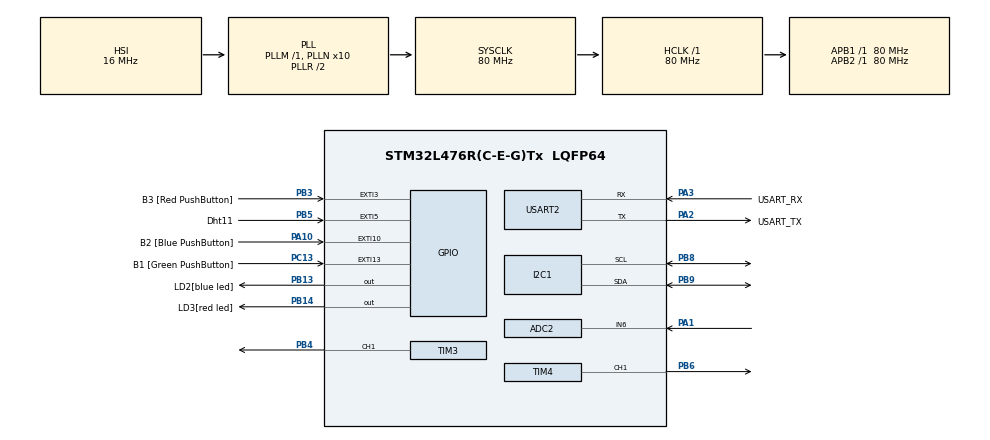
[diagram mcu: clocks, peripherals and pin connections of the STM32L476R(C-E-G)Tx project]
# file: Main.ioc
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ADC2.Channel-0\#ChannelRegularConversion=ADC_CHANNEL_6
ADC2.ClockPrescaler=ADC_CLOCK_ASYNC_DIV64
ADC2.ContinuousConvMode=ENABLE
ADC2.NbrOfConversionFlag=1
ADC2.OffsetNumber-0\#ChannelRegularConversion=ADC_OFFSET_NONE
ADC2.Rank-0\#ChannelRegularConversion=1
ADC2.SamplingTime-0\#ChannelRegularConversion=ADC_SAMPLETIME_2CYCLES_5
I2C1.Timing=0x10909CEC
Mcu.Family=STM32L4
Mcu.Name=STM32L476R(C-E-G)Tx
Mcu.Package=LQFP64
NVIC.ADC1_2_IRQn=true\:0\:0\:false\:false\:true\:true\:true\:true
NVIC.EXTI15_10_IRQn=true\:0\:0\:false\:false\:true\:true\:true\:true
NVIC.EXTI3_IRQn=true\:0\:0\:false\:false\:true\:true\:true\:true
NVIC.EXTI9_5_IRQn=true\:0\:0\:false\:false\:true\:true\:true\:true
NVIC.FLASH_IRQn=true\:0\:0\:false\:false\:true\:true\:true\:true
NVIC.PriorityGroup=NVIC_PRIORITYGROUP_4
NVIC.TIM3_IRQn=true\:0\:0\:false\:false\:true\:true\:true\:true
NVIC.TIM4_IRQn=true\:0\:0\:false\:false\:true\:true\:true\:true
NVIC.TIM6_DAC_IRQn=true\:0\:0\:false\:false\:true\:true\:true\:true
NVIC.USART2_IRQn=true\:0\:0\:false\:false\:true\:true\:true\:true
PA1.Signal=ADCx_IN6
PA10.GPIO_Label=B2 [Blue PushButton]
PA10.GPIO_ModeDefaultEXTI=GPIO_MODE_IT_RISING_FALLING
PA10.Signal=GPXTI10
PA13\ (JTMS-SWDIO).GPIO_Label=TMS
PA13\ (JTMS-SWDIO).Mode=Serial_Wire
PA13\ (JTMS-SWDIO).Signal=SYS_JTMS-SWDIO
PA14\ (JTCK-SWCLK).GPIO_Label=TCK
PA14\ (JTCK-SWCLK).Mode=Serial_Wire
PA14\ (JTCK-SWCLK).Signal=SYS_JTCK-SWCLK
PA2.GPIO_Label=USART_TX
PA2.GPIO_Mode=GPIO_MODE_AF_PP
PA2.GPIO_PuPd=GPIO_NOPULL
PA2.GPIO_Speed=GPIO_SPEED_FREQ_VERY_HIGH
PA2.Mode=Asynchronous
PA2.Signal=USART2_TX
PA3.GPIO_Label=USART_RX
PA3.GPIO_Mode=GPIO_MODE_AF_PP
PA3.GPIO_PuPd=GPIO_NOPULL
PA3.GPIO_Speed=GPIO_SPEED_FREQ_VERY_HIGH
PA3.Mode=Asynchronous
PA3.Signal=USART2_RX
PB13.GPIO_Label=LD2[blue led]
PB13.Signal=GPIO_Output
PB14.GPIO_Label=LD3[red led]
PB14.Signal=GPIO_Output
PB3\ (JTDO-TRACESWO).GPIO_Label=B3 [Red PushButton]
PB3\ (JTDO-TRACESWO).GPIO_ModeDefaultEXTI=GPIO_MODE_IT_FALLING
PB3\ (JTDO-TRACESWO).Signal=GPXTI3
PB4\ (NJTRST).Signal=S_TIM3_CH1
PB5.GPIO_Label=Dht11
PB5.GPIO_ModeDefaultEXTI=GPIO_MODE_IT_FALLING
PB5.Signal=GPXTI5
PB6.Signal=S_TIM4_CH1
PB8.Mode=I2C
PB8.Signal=I2C1_SCL
PB9.Mode=I2C
PB9.Signal=I2C1_SDA
PC13.GPIO_Label=B1 [Green PushButton]
PC13.GPIO_ModeDefaultEXTI=GPIO_MODE_IT_FALLING
PC13.GPIO_PuPd=GPIO_NOPULL
PC13.Signal=GPXTI13
PC14-OSC32_IN\ (PC14).Mode=LSE-External-Oscillator
PC14-OSC32_IN\ (PC14).Signal=RCC_OSC32_IN
PC15-OSC32_OUT\ (PC15).Mode=LSE-External-Oscillator
PC15-OSC32_OUT\ (PC15).Signal=RCC_OSC32_OUT
PH0-OSC_IN\ (PH0).Signal=RCC_OSC_IN
PH1-OSC_OUT\ (PH1).Signal=RCC_OSC_OUT
ProjectManager.HeapSize=0x200
ProjectManager.StackSize=0x400
ProjectManager.TargetToolchain=STM32CubeIDE
RCC.ADCFreq_Value=64000000
RCC.AHBFreq_Value=80000000
RCC.APB1Freq_Value=80000000
RCC.APB1TimFreq_Value=80000000
RCC.APB2Freq_Value=80000000
RCC.APB2TimFreq_Value=80000000
RCC.CortexFreq_Value=80000000
RCC.HCLKFreq_Value=80000000
RCC.HSE_VALUE=8000000
RCC.HSI_VALUE=16000000
RCC.MSI_VALUE=4000000
RCC.PLLN=10
RCC.PLLSourceVirtual=RCC_PLLSOURCE_HSI
RCC.PREFETCH_ENABLE=1
RCC.SYSCLKFreq_VALUE=80000000
RCC.SYSCLKSource=RCC_SYSCLKSOURCE_PLLCLK
RCC.USBFreq_Value=64000000
RCC.VCOOutputFreq_Value=160000000
SH.ADCx_IN6.0=ADC2_IN6,IN6-Single-Ended
SH.S_TIM3_CH1.0=TIM3_CH1,PWM Generation1 CH1
SH.S_TIM4_CH1.0=TIM4_CH1,PWM Generation1 CH1
TIM16.Prescaler=80
TIM3.Channel-PWM\ Generation1\ CH1=TIM_CHANNEL_1
TIM3.Period=100
TIM3.Prescaler=799
TIM3.Pulse-PWM\ Generation1\ CH1=50
TIM4.Channel-PWM\ Generation1\ CH1=TIM_CHANNEL_1
TIM4.Period=100
TIM4.Prescaler=7999
TIM6.Period=10
TIM6.Prescaler=7999
USART2.VirtualMode-Asynchronous=VM_ASYNC
VP_TIM16_VS_ClockSourceINT.Mode=Enable_Timer
VP_TIM3_VS_ClockSourceINT.Mode=Internal
VP_TIM6_VS_ClockSourceINT.Mode=Enable_Timer
board=NUCLEO-L476RG

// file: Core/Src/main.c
/* USER CODE BEGIN Header */
/**
  ******************************************************************************
  * @file           : main.c
  * @brief          : Main program body
  ******************************************************************************
  * @attention
  *
  * Copyright (c) 2022 STMicroelectronics.
  * All rights reserved.
  *
  * This software is licensed under terms that can be found in the LICENSE file
  * in the root directory of this software component.
  * If no LICENSE file comes with this software, it is provided AS-IS.
  *
  ******************************************************************************
  */
/* USER CODE END Header */
#include "main.h"

/* USER CODE BEGIN Includes */
#include "myMain.h"
/* USER CODE END Includes */

 ADC_HandleTypeDef hadc2;

I2C_HandleTypeDef hi2c1;

TIM_HandleTypeDef htim3;
TIM_HandleTypeDef htim4;
TIM_HandleTypeDef htim6;
TIM_HandleTypeDef htim16;

UART_HandleTypeDef huart2;

void SystemClock_Config(void);
static void MX_GPIO_Init(void);
static void MX_USART2_UART_Init(void);
static void MX_TIM6_Init(void);
static void MX_TIM3_Init(void);
static void MX_TIM4_Init(void);
static void MX_ADC2_Init(void);
static void MX_TIM16_Init(void);
static void MX_I2C1_Init(void);

int main(void)
{

  /* MCU Configuration--------------------------------------------------------*/

  /* Reset of all peripherals, Initializes the Flash interface and the Systick. */
  HAL_Init();

  /* Configure the system clock */
  SystemClock_Config();

  /* Initialize all configured peripherals */
  MX_GPIO_Init();
  MX_USART2_UART_Init();
  MX_TIM6_Init();
  MX_TIM3_Init();
  MX_TIM4_Init();
  MX_ADC2_Init();
  MX_TIM16_Init();
  MX_I2C1_Init();
  /* USER CODE BEGIN 2 */
  mainloop();
  /* USER CODE END 2 */

  /* Infinite loop */
  while (1)
  {

  }
}

void SystemClock_Config(void)
{
  RCC_OscInitTypeDef RCC_OscInitStruct = {0};
  RCC_ClkInitTypeDef RCC_ClkInitStruct = {0};

  /** Configure the main internal regulator output voltage
  */
  if (HAL_PWREx_ControlVoltageScaling(PWR_REGULATOR_VOLTAGE_SCALE1) != HAL_OK)
  {
    Error_Handler();
  }

  /** Initializes the RCC Oscillators according to the specified parameters
  * in the RCC_OscInitTypeDef structure.
  */
  RCC_OscInitStruct.OscillatorType = RCC_OSCILLATORTYPE_HSI;
  RCC_OscInitStruct.HSIState = RCC_HSI_ON;
  RCC_OscInitStruct.HSICalibrationValue = RCC_HSICALIBRATION_DEFAULT;
  RCC_OscInitStruct.PLL.PLLState = RCC_PLL_ON;
  RCC_OscInitStruct.PLL.PLLSource = RCC_PLLSOURCE_HSI;
  RCC_OscInitStruct.PLL.PLLM = 1;
  RCC_OscInitStruct.PLL.PLLN = 10;
  RCC_OscInitStruct.PLL.PLLP = RCC_PLLP_DIV7;
  RCC_OscInitStruct.PLL.PLLQ = RCC_PLLQ_DIV2;
  RCC_OscInitStruct.PLL.PLLR = RCC_PLLR_DIV2;
  if (HAL_RCC_OscConfig(&RCC_OscInitStruct) != HAL_OK)
  {
    Error_Handler();
  }

  /** Initializes the CPU, AHB and APB buses clocks
  */
  RCC_ClkInitStruct.ClockType = RCC_CLOCKTYPE_HCLK|RCC_CLOCKTYPE_SYSCLK
                              |RCC_CLOCKTYPE_PCLK1|RCC_CLOCKTYPE_PCLK2;
  RCC_ClkInitStruct.SYSCLKSource = RCC_SYSCLKSOURCE_PLLCLK;
  RCC_ClkInitStruct.AHBCLKDivider = RCC_SYSCLK_DIV1;
  RCC_ClkInitStruct.APB1CLKDivider = RCC_HCLK_DIV1;
  RCC_ClkInitStruct.APB2CLKDivider = RCC_HCLK_DIV1;

  if (HAL_RCC_ClockConfig(&RCC_ClkInitStruct, FLASH_LATENCY_4) != HAL_OK)
  {
    Error_Handler();
  }
}

static void MX_ADC2_Init(void)
{

  ADC_ChannelConfTypeDef sConfig = {0};

  /** Common config
  */
  hadc2.Instance = ADC2;
  hadc2.Init.ClockPrescaler = ADC_CLOCK_ASYNC_DIV64;
  hadc2.Init.Resolution = ADC_RESOLUTION_12B;
  hadc2.Init.DataAlign = ADC_DATAALIGN_RIGHT;
  hadc2.Init.ScanConvMode = ADC_SCAN_DISABLE;
  hadc2.Init.EOCSelection = ADC_EOC_SINGLE_CONV;
  hadc2.Init.LowPowerAutoWait = DISABLE;
  hadc2.Init.ContinuousConvMode = ENABLE;
  hadc2.Init.NbrOfConversion = 1;
  hadc2.Init.DiscontinuousConvMode = DISABLE;
  hadc2.Init.ExternalTrigConv = ADC_SOFTWARE_START;
  hadc2.Init.ExternalTrigConvEdge = ADC_EXTERNALTRIGCONVEDGE_NONE;
  hadc2.Init.DMAContinuousRequests = DISABLE;
  hadc2.Init.Overrun = ADC_OVR_DATA_PRESERVED;
  hadc2.Init.OversamplingMode = DISABLE;
  if (HAL_ADC_Init(&hadc2) != HAL_OK)
  {
    Error_Handler();
  }

  /** Configure Regular Channel
  */
  sConfig.Channel = ADC_CHANNEL_6;
  sConfig.Rank = ADC_REGULAR_RANK_1;
  sConfig.SamplingTime = ADC_SAMPLETIME_2CYCLES_5;
  sConfig.SingleDiff = ADC_SINGLE_ENDED;
  sConfig.OffsetNumber = ADC_OFFSET_NONE;
  sConfig.Offset = 0;
  if (HAL_ADC_ConfigChannel(&hadc2, &sConfig) != HAL_OK)
  {
    Error_Handler();
  }

}

static void MX_I2C1_Init(void)
{

  hi2c1.Instance = I2C1;
  hi2c1.Init.Timing = 0x10909CEC;
  hi2c1.Init.OwnAddress1 = 0;
  hi2c1.Init.AddressingMode = I2C_ADDRESSINGMODE_7BIT;
  hi2c1.Init.DualAddressMode = I2C_DUALADDRESS_DISABLE;
  hi2c1.Init.OwnAddress2 = 0;
  hi2c1.Init.OwnAddress2Masks = I2C_OA2_NOMASK;
  hi2c1.Init.GeneralCallMode = I2C_GENERALCALL_DISABLE;
  hi2c1.Init.NoStretchMode = I2C_NOSTRETCH_DISABLE;
  if (HAL_I2C_Init(&hi2c1) != HAL_OK)
  {
    Error_Handler();
  }

  /** Configure Analogue filter
  */
  if (HAL_I2CEx_ConfigAnalogFilter(&hi2c1, I2C_ANALOGFILTER_ENABLE) != HAL_OK)
  {
    Error_Handler();
  }

  /** Configure Digital filter
  */
  if (HAL_I2CEx_ConfigDigitalFilter(&hi2c1, 0) != HAL_OK)
  {
    Error_Handler();
  }

}

static void MX_TIM3_Init(void)
{

  TIM_ClockConfigTypeDef sClockSourceConfig = {0};
  TIM_MasterConfigTypeDef sMasterConfig = {0};
  TIM_OC_InitTypeDef sConfigOC = {0};

  htim3.Instance = TIM3;
  htim3.Init.Prescaler = 799;
  htim3.Init.CounterMode = TIM_COUNTERMODE_UP;
  htim3.Init.Period = 100;
  htim3.Init.ClockDivision = TIM_CLOCKDIVISION_DIV1;
  htim3.Init.AutoReloadPreload = TIM_AUTORELOAD_PRELOAD_DISABLE;
  if (HAL_TIM_Base_Init(&htim3) != HAL_OK)
  {
    Error_Handler();
  }
  sClockSourceConfig.ClockSource = TIM_CLOCKSOURCE_INTERNAL;
  if (HAL_TIM_ConfigClockSource(&htim3, &sClockSourceConfig) != HAL_OK)
  {
    Error_Handler();
  }
  if (HAL_TIM_PWM_Init(&htim3) != HAL_OK)
  {
    Error_Handler();
  }
  sMasterConfig.MasterOutputTrigger = TIM_TRGO_RESET;
  sMasterConfig.MasterSlaveMode = TIM_MASTERSLAVEMODE_DISABLE;
  if (HAL_TIMEx_MasterConfigSynchronization(&htim3, &sMasterConfig) != HAL_OK)
  {
    Error_Handler();
  }
  sConfigOC.OCMode = TIM_OCMODE_PWM1;
  sConfigOC.Pulse = 50;
  sConfigOC.OCPolarity = TIM_OCPOLARITY_HIGH;
  sConfigOC.OCFastMode = TIM_OCFAST_DISABLE;
  if (HAL_TIM_PWM_ConfigChannel(&htim3, &sConfigOC, TIM_CHANNEL_1) != HAL_OK)
  {
    Error_Handler();
  }
  HAL_TIM_MspPostInit(&htim3);

}

static void MX_TIM4_Init(void)
{

  TIM_MasterConfigTypeDef sMasterConfig = {0};
  TIM_OC_InitTypeDef sConfigOC = {0};

  htim4.Instance = TIM4;
  htim4.Init.Prescaler = 7999;
  htim4.Init.CounterMode = TIM_COUNTERMODE_UP;
  htim4.Init.Period = 100;
  htim4.Init.ClockDivision = TIM_CLOCKDIVISION_DIV1;
  htim4.Init.AutoReloadPreload = TIM_AUTORELOAD_PRELOAD_DISABLE;
  if (HAL_TIM_PWM_Init(&htim4) != HAL_OK)
  {
    Error_Handler();
  }
  sMasterConfig.MasterOutputTrigger = TIM_TRGO_RESET;
  sMasterConfig.MasterSlaveMode = TIM_MASTERSLAVEMODE_DISABLE;
  if (HAL_TIMEx_MasterConfigSynchronization(&htim4, &sMasterConfig) != HAL_OK)
  {
    Error_Handler();
  }
  sConfigOC.OCMode = TIM_OCMODE_PWM1;
  sConfigOC.Pulse = 0;
  sConfigOC.OCPolarity = TIM_OCPOLARITY_HIGH;
  sConfigOC.OCFastMode = TIM_OCFAST_DISABLE;
  if (HAL_TIM_PWM_ConfigChannel(&htim4, &sConfigOC, TIM_CHANNEL_1) != HAL_OK)
  {
    Error_Handler();
  }
  HAL_TIM_MspPostInit(&htim4);

}

static void MX_TIM6_Init(void)
{

  TIM_MasterConfigTypeDef sMasterConfig = {0};

  htim6.Instance = TIM6;
  htim6.Init.Prescaler = 7999;
  htim6.Init.CounterMode = TIM_COUNTERMODE_UP;
  htim6.Init.Period = 10;
  htim6.Init.AutoReloadPreload = TIM_AUTORELOAD_PRELOAD_DISABLE;
  if (HAL_TIM_Base_Init(&htim6) != HAL_OK)
  {
    Error_Handler();
  }
  sMasterConfig.MasterOutputTrigger = TIM_TRGO_RESET;
  sMasterConfig.MasterSlaveMode = TIM_MASTERSLAVEMODE_DISABLE;
  if (HAL_TIMEx_MasterConfigSynchronization(&htim6, &sMasterConfig) != HAL_OK)
  {
    Error_Handler();
  }

}

static void MX_TIM16_Init(void)
{

  htim16.Instance = TIM16;
  htim16.Init.Prescaler = 80;
  htim16.Init.CounterMode = TIM_COUNTERMODE_UP;
  htim16.Init.Period = 65535;
  htim16.Init.ClockDivision = TIM_CLOCKDIVISION_DIV1;
  htim16.Init.RepetitionCounter = 0;
  htim16.Init.AutoReloadPreload = TIM_AUTORELOAD_PRELOAD_DISABLE;
  if (HAL_TIM_Base_Init(&htim16) != HAL_OK)
  {
    Error_Handler();
  }

}

static void MX_USART2_UART_Init(void)
{

  huart2.Instance = USART2;
  huart2.Init.BaudRate = 115200;
  huart2.Init.WordLength = UART_WORDLENGTH_8B;
  huart2.Init.StopBits = UART_STOPBITS_1;
  huart2.Init.Parity = UART_PARITY_NONE;
  huart2.Init.Mode = UART_MODE_TX_RX;
  huart2.Init.HwFlowCtl = UART_HWCONTROL_NONE;
  huart2.Init.OverSampling = UART_OVERSAMPLING_16;
  huart2.Init.OneBitSampling = UART_ONE_BIT_SAMPLE_DISABLE;
  huart2.AdvancedInit.AdvFeatureInit = UART_ADVFEATURE_NO_INIT;
  if (HAL_UART_Init(&huart2) != HAL_OK)
  {
    Error_Handler();
  }

}

static void MX_GPIO_Init(void)
{
  GPIO_InitTypeDef GPIO_InitStruct = {0};

  /* GPIO Ports Clock Enable */
  __HAL_RCC_GPIOC_CLK_ENABLE();
  __HAL_RCC_GPIOH_CLK_ENABLE();
  __HAL_RCC_GPIOA_CLK_ENABLE();
  __HAL_RCC_GPIOB_CLK_ENABLE();

  /*Configure GPIO pin Output Level */
  HAL_GPIO_WritePin(GPIOB, LD2_Pin|LD3_Pin, GPIO_PIN_RESET);

  /*Configure GPIO pin : B1_Pin */
  GPIO_InitStruct.Pin = B1_Pin;
  GPIO_InitStruct.Mode = GPIO_MODE_IT_FALLING;
  GPIO_InitStruct.Pull = GPIO_NOPULL;
  HAL_GPIO_Init(B1_GPIO_Port, &GPIO_InitStruct);

  /*Configure GPIO pins : LD2_Pin LD3_Pin */
  GPIO_InitStruct.Pin = LD2_Pin|LD3_Pin;
  GPIO_InitStruct.Mode = GPIO_MODE_OUTPUT_PP;
  GPIO_InitStruct.Pull = GPIO_NOPULL;
  GPIO_InitStruct.Speed = GPIO_SPEED_FREQ_LOW;
  HAL_GPIO_Init(GPIOB, &GPIO_InitStruct);

  /*Configure GPIO pin : B2_Pin */
  GPIO_InitStruct.Pin = B2_Pin;
  GPIO_InitStruct.Mode = GPIO_MODE_IT_RISING_FALLING;
  GPIO_InitStruct.Pull = GPIO_NOPULL;
  HAL_GPIO_Init(B2_GPIO_Port, &GPIO_InitStruct);

  /*Configure GPIO pins : B3_Pin Dht11_Pin */
  GPIO_InitStruct.Pin = B3_Pin|Dht11_Pin;
  GPIO_InitStruct.Mode = GPIO_MODE_IT_FALLING;
  GPIO_InitStruct.Pull = GPIO_NOPULL;
  HAL_GPIO_Init(GPIOB, &GPIO_InitStruct);

  /* EXTI interrupt init*/
  HAL_NVIC_SetPriority(EXTI3_IRQn, 0, 0);
  HAL_NVIC_EnableIRQ(EXTI3_IRQn);

  HAL_NVIC_SetPriority(EXTI9_5_IRQn, 0, 0);
  HAL_NVIC_EnableIRQ(EXTI9_5_IRQn);

  HAL_NVIC_SetPriority(EXTI15_10_IRQn, 0, 0);
  HAL_NVIC_EnableIRQ(EXTI15_10_IRQn);

}

void Error_Handler(void)
{
  __disable_irq();
  while (1)
  {
  }
}
